# CY8C5888LTI_LP097 register map
File version: 0.1
CY8C58LP
Registers are 8-bit, read-write, no defined reset value unless marked. A register's access mark holds for its fields unless they carry their own. Offsets are from the block's base; lines under a group give offsets from that group; [hi:lo] are bit positions; {n}, {i} and the like mark numbered series; 'fields as' and 'values as' point back to an identical list; <NAME> marks a mode.

## Memory map
0x00000000 SPIS
0x00000000 USBFS
0x00000000 I2S_1

## SPIS
Base 0x00000000
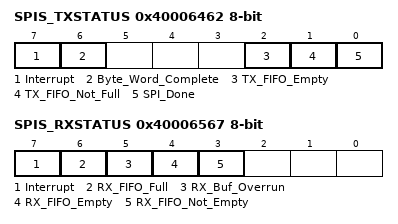
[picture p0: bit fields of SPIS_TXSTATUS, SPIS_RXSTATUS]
0x40006462 SPIS_TXSTATUS
  [7] Interrupt ro — Set when interrupt occurs
  [6] Byte_Word_Complete ro — Set when a byte/word transmit has completed
  [2] TX_FIFO_Empty ro — Set when the TX Data FIFO is empty
  [1] TX_FIFO_Not_Full ro — Set when the TX Data FIFO is not full
  [0] SPI_Done ro — Set when all of the data in the transmit FIFO has been sent. Set when Byte/Word Complete has been set and TX Data FIFO is empty
0x40006505 SPIS_RX_DATA
0x40006505 SPIS_TX_DATA
0x40006567 SPIS_RXSTATUS
  [7] Interrupt ro — Set when interrupt occurs
  [6] RX_FIFO_Full ro — Set when the RX Data FIFO is full
  [5] RX_Buf_Overrun ro — Set when RX Data has overrun the 4 byte/word FIFO without being moved to the RX buffer cmemory array (if one exists)
  [4] RX_FIFO_Empty ro — Set when the RX Data FIFO is empty
  [3] RX_FIFO_Not_Empty ro — Set when the RX Data FIFO is not empty. That is, at least one byte/word is in the RX FIFO

## I2S_1
Base 0x00000000
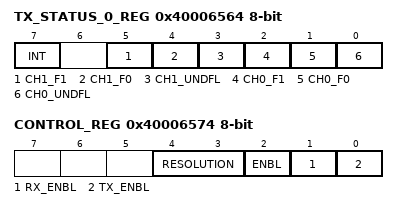
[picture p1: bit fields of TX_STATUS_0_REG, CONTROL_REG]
0x40006564 TX_STATUS_0_REG
  [7] INT ro — Interrupt bit
  [5] CH1_F1 ro — Stereo channel 1 FIFO 1 state
    0=FULL; 1=NOT_FULL
  [4] CH1_F0 ro — Stereo channel 1 FIFO 0 state
    0=FULL; 1=NOT_FULL
  [3] CH1_UNDFL ro — Stereo channel 1 FIFO underflow
    0=NO_UNDERFLOW; 1=UNDERFLOW
  [2] CH0_F1 ro — Stereo channel 0 FIFO 1 state
    0=FULL; 1=NOT_FULL
  [1] CH0_F0 ro — Stereo channel 0 FIFO 0 state
    0=FULL; 1=NOT_FULL
  [0] CH0_UNDFL ro — Stereo channel 0 FIFO underflow
    0=NO_UNDERFLOW; 1=UNDERFLOW
0x40006574 CONTROL_REG
  [4:3] RESOLUTION — Specifies data bits value. Applicable only if dynamic bit resolution is selected.
    0=8_BIT; 1=16_BIT; 2=24_BIT; 3=32_BIT
  [2] ENBL — Starts the generation of the WS and SCK outputs.
    1=ENABLED; 0=DISABLED
  [1] RX_ENBL — Enables Rx direction. Applicable only if Rx direction presents for the component.
    1=ENABLED; 0=DISABLED
  [0] TX_ENBL — Enables Tx direction. Applicable only if Tx direction presents for the component.
    1=ENABLED; 0=DISABLED
